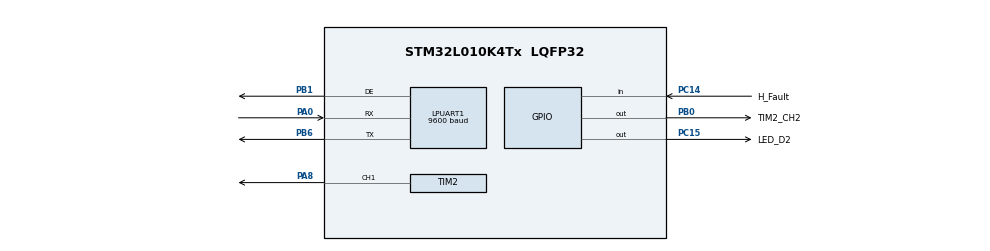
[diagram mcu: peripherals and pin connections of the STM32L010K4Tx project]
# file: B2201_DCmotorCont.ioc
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LPUART1.BaudRate=9600
LPUART1.WordLength=UART_WORDLENGTH_8B
Mcu.Family=STM32L0
Mcu.Name=STM32L010K4Tx
Mcu.Package=LQFP32
PA0-CK_IN.Mode=Asynchronous
PA0-CK_IN.Signal=LPUART1_RX
PA13.Mode=Serial_Wire
PA13.Signal=SYS_SWDIO
PA14.Mode=Serial_Wire
PA14.Signal=SYS_SWCLK
PA8.Signal=S_TIM2_CH1
PB0.GPIO_Label=TIM2_CH2
PB0.Signal=GPIO_Output
PB1.Mode=Hardware Flow Control (RS485)
PB1.Signal=LPUART1_DE
PB6.Mode=Asynchronous
PB6.Signal=LPUART1_TX
PC14-OSC32_IN.GPIO_Label=H_Fault
PC14-OSC32_IN.Signal=GPIO_Input
PC15-OSC32_OUT.GPIO_Label=LED_D2
PC15-OSC32_OUT.Signal=GPIO_Output
ProjectManager.HeapSize=0x200
ProjectManager.StackSize=0x400
ProjectManager.TargetToolchain=STM32CubeIDE
RCC.ADCFreq_Value=16000000
RCC.AHBFreq_Value=24000000
RCC.APB1Freq_Value=24000000
RCC.APB1TimFreq_Value=24000000
RCC.APB2Freq_Value=24000000
RCC.APB2TimFreq_Value=24000000
RCC.HCLKFreq_Value=24000000
RCC.HSE_VALUE=8000000
RCC.HSI16_VALUE=16000000
RCC.HSI_VALUE=16000000
RCC.LSE_VALUE=32768
RCC.MSIClockRange=RCC_MSIRANGE_6
RCC.MSI_VALUE=4194000
RCC.RCC_TIM_PRescaler_Selection=RCC_TIMPRES_DESACTIVATED
RCC.SYSCLKFreq_VALUE=24000000
RCC.SYSCLKSource=RCC_SYSCLKSOURCE_PLLCLK
RCC.VCOOutputFreq_Value=48000000
SH.S_TIM2_CH1.0=TIM2_CH1,PWM Generation1 CH1
TIM2.Channel-PWM\ Generation1\ CH1=TIM_CHANNEL_1
TIM2.Period=1000
TIM2.Prescaler=0
TIM2.Pulse-PWM\ Generation1\ CH1=90
VP_LPTIM1_VS_LPTIM_counterModeInternalClock.Mode=Counts__internal_clock_event_00
VP_TIM21_VS_ClockSourceINT.Mode=Internal
VP_TIM2_VS_ClockSourceINT.Mode=Internal
board=custom

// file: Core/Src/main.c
/* USER CODE BEGIN Header */
/**
  ******************************************************************************
  * @file           : main.c
  * @brief          : Main program body
  ******************************************************************************
  * @attention
  *
  * Copyright (c) 2022 STMicroelectronics.
  * All rights reserved.
  *
  * This software is licensed under terms that can be found in the LICENSE file
  * in the root directory of this software component.
  * If no LICENSE file comes with this software, it is provided AS-IS.
  *
  ******************************************************************************
  */
/* USER CODE END Header */
#include "main.h"

/* USER CODE BEGIN Includes */
#include "stdio.h"

/* USER CODE END Includes */

LPTIM_HandleTypeDef hlptim1;

UART_HandleTypeDef hlpuart1;

TIM_HandleTypeDef htim2;
TIM_HandleTypeDef htim21;

/* USER CODE BEGIN PV */
uint16_t value_adc;
uint16_t counter_global;

/* USER CODE END PV */

void SystemClock_Config(void);
static void MX_GPIO_Init(void);
static void MX_LPUART1_UART_Init(void);
static void MX_TIM2_Init(void);
static void MX_TIM21_Init(void);
static void MX_LPTIM1_Init(void);

/* USER CODE BEGIN 0 */
// connect printf to lpuart1 ** used too much memory so I had to remove it
//int _write(int file, char *ptr, int len)
//{
//	HAL_UART_Transmit(&hlpuart1, (uint8_t*)ptr, len, HAL_MAX_DELAY);
//	return len;
//}

/* USER CODE END 0 */

int main(void)
{

  /* MCU Configuration--------------------------------------------------------*/

  /* Reset of all peripherals, Initializes the Flash interface and the Systick. */
  HAL_Init();

  /* Configure the system clock */
  SystemClock_Config();

  /* Initialize all configured peripherals */
  MX_GPIO_Init();
  MX_LPUART1_UART_Init();
  MX_TIM2_Init();
  MX_TIM21_Init();
  MX_LPTIM1_Init();
  /* USER CODE BEGIN 2 */
//  HAL_ADCEx_Calibration_Start(&hadc, ADC_SINGLE_ENDED);
//  HAL_ADC_Start_DMA(&hadc, (uint32_t*)&value_adc, 1);
  HAL_TIM_PWM_Start(&htim2, TIM_CHANNEL_1);

//  printf("GPIO Init Done /r/n");
  /* USER CODE END 2 */

  /* Infinite loop */
  /* USER CODE BEGIN WHILE */
	int counter =0;

  while (1)
  {

    /* USER CODE END WHILE */

    /* USER CODE BEGIN 3 */

  //-------------------------------------------------
//	  HAL_ADC_Start(&hadc);
//	  printf("current count is: %d\r\n", counter++);
	  counter_global=counter;
	  HAL_Delay(100);
	  HAL_GPIO_WritePin(TIM2_CH2_GPIO_Port, TIM2_CH2_Pin, 1);
      __HAL_TIM_SET_COMPARE(&htim2, TIM_CHANNEL_1,counter); // update pwm compare
      if (counter <1000){
    	  counter++;
      }else counter =0;

/* GPIO Mode simple on off...
     // Forward
	  HAL_GPIO_WritePin(ToshibaIN1_GPIO_Port, ToshibaIN1_Pin, 1);
	  HAL_GPIO_WritePin(ToshibaIN2_GPIO_Port, ToshibaIN2_Pin, 0);
	  HAL_Delay(1000);

	  //coast
	  HAL_GPIO_WritePin(ToshibaIN1_GPIO_Port, ToshibaIN1_Pin, 0);
	  HAL_GPIO_WritePin(ToshibaIN2_GPIO_Port, ToshibaIN2_Pin, 0);
	  HAL_Delay(2000);

	  //reverse
	  HAL_GPIO_WritePin(ToshibaIN1_GPIO_Port, ToshibaIN1_Pin, 0);
	  HAL_GPIO_WritePin(ToshibaIN2_GPIO_Port, ToshibaIN2_Pin, 1);
	  HAL_Delay(1000);

	  //break
	  HAL_GPIO_WritePin(ToshibaIN1_GPIO_Port, ToshibaIN1_Pin, 1);
	  HAL_GPIO_WritePin(ToshibaIN2_GPIO_Port, ToshibaIN2_Pin, 1);
	  HAL_Delay(2000);
*/

	  HAL_GPIO_TogglePin(LED_D2_GPIO_Port, LED_D2_Pin);

  }
  /* USER CODE END 3 */
}

void SystemClock_Config(void)
{
  LL_FLASH_SetLatency(LL_FLASH_LATENCY_1);
  while(LL_FLASH_GetLatency()!= LL_FLASH_LATENCY_1)
  {
  }
  LL_PWR_SetRegulVoltageScaling(LL_PWR_REGU_VOLTAGE_SCALE1);
  LL_RCC_HSI_Enable();

   /* Wait till HSI is ready */
  while(LL_RCC_HSI_IsReady() != 1)
  {

  }
  LL_RCC_HSI_SetCalibTrimming(16);
  LL_RCC_PLL_ConfigDomain_SYS(LL_RCC_PLLSOURCE_HSI, LL_RCC_PLL_MUL_3, LL_RCC_PLL_DIV_2);
  LL_RCC_PLL_Enable();

   /* Wait till PLL is ready */
  while(LL_RCC_PLL_IsReady() != 1)
  {

  }
  LL_RCC_SetAHBPrescaler(LL_RCC_SYSCLK_DIV_1);
  LL_RCC_SetAPB1Prescaler(LL_RCC_APB1_DIV_1);
  LL_RCC_SetAPB2Prescaler(LL_RCC_APB2_DIV_1);
  LL_RCC_SetSysClkSource(LL_RCC_SYS_CLKSOURCE_PLL);

   /* Wait till System clock is ready */
  while(LL_RCC_GetSysClkSource() != LL_RCC_SYS_CLKSOURCE_STATUS_PLL)
  {

  }
  LL_SetSystemCoreClock(24000000);

   /* Update the time base */
  if (HAL_InitTick (TICK_INT_PRIORITY) != HAL_OK)
  {
    Error_Handler();
  }
  LL_RCC_SetLPUARTClockSource(LL_RCC_LPUART1_CLKSOURCE_PCLK1);
  LL_RCC_SetLPTIMClockSource(LL_RCC_LPTIM1_CLKSOURCE_PCLK1);
}

static void MX_LPTIM1_Init(void)
{

  hlptim1.Instance = LPTIM1;
  hlptim1.Init.Clock.Source = LPTIM_CLOCKSOURCE_APBCLOCK_LPOSC;
  hlptim1.Init.Clock.Prescaler = LPTIM_PRESCALER_DIV1;
  hlptim1.Init.Trigger.Source = LPTIM_TRIGSOURCE_SOFTWARE;
  hlptim1.Init.OutputPolarity = LPTIM_OUTPUTPOLARITY_HIGH;
  hlptim1.Init.UpdateMode = LPTIM_UPDATE_IMMEDIATE;
  hlptim1.Init.CounterSource = LPTIM_COUNTERSOURCE_INTERNAL;
  if (HAL_LPTIM_Init(&hlptim1) != HAL_OK)
  {
    Error_Handler();
  }

}

static void MX_LPUART1_UART_Init(void)
{

  hlpuart1.Instance = LPUART1;
  hlpuart1.Init.BaudRate = 9600;
  hlpuart1.Init.WordLength = UART_WORDLENGTH_8B;
  hlpuart1.Init.StopBits = UART_STOPBITS_1;
  hlpuart1.Init.Parity = UART_PARITY_NONE;
  hlpuart1.Init.Mode = UART_MODE_TX_RX;
  hlpuart1.Init.HwFlowCtl = UART_HWCONTROL_NONE;
  hlpuart1.Init.OneBitSampling = UART_ONE_BIT_SAMPLE_DISABLE;
  hlpuart1.AdvancedInit.AdvFeatureInit = UART_ADVFEATURE_NO_INIT;
  if (HAL_RS485Ex_Init(&hlpuart1, UART_DE_POLARITY_HIGH, 0, 0) != HAL_OK)
  {
    Error_Handler();
  }

}

static void MX_TIM2_Init(void)
{

  TIM_ClockConfigTypeDef sClockSourceConfig = {0};
  TIM_MasterConfigTypeDef sMasterConfig = {0};
  TIM_OC_InitTypeDef sConfigOC = {0};

  htim2.Instance = TIM2;
  htim2.Init.Prescaler = 0;
  htim2.Init.CounterMode = TIM_COUNTERMODE_UP;
  htim2.Init.Period = 1000;
  htim2.Init.ClockDivision = TIM_CLOCKDIVISION_DIV1;
  htim2.Init.AutoReloadPreload = TIM_AUTORELOAD_PRELOAD_DISABLE;
  if (HAL_TIM_Base_Init(&htim2) != HAL_OK)
  {
    Error_Handler();
  }
  sClockSourceConfig.ClockSource = TIM_CLOCKSOURCE_INTERNAL;
  if (HAL_TIM_ConfigClockSource(&htim2, &sClockSourceConfig) != HAL_OK)
  {
    Error_Handler();
  }
  if (HAL_TIM_PWM_Init(&htim2) != HAL_OK)
  {
    Error_Handler();
  }
  sMasterConfig.MasterOutputTrigger = TIM_TRGO_RESET;
  sMasterConfig.MasterSlaveMode = TIM_MASTERSLAVEMODE_DISABLE;
  if (HAL_TIMEx_MasterConfigSynchronization(&htim2, &sMasterConfig) != HAL_OK)
  {
    Error_Handler();
  }
  sConfigOC.OCMode = TIM_OCMODE_PWM1;
  sConfigOC.Pulse = 90;
  sConfigOC.OCPolarity = TIM_OCPOLARITY_HIGH;
  sConfigOC.OCFastMode = TIM_OCFAST_DISABLE;
  if (HAL_TIM_PWM_ConfigChannel(&htim2, &sConfigOC, TIM_CHANNEL_1) != HAL_OK)
  {
    Error_Handler();
  }
  HAL_TIM_MspPostInit(&htim2);

}

static void MX_TIM21_Init(void)
{

  TIM_ClockConfigTypeDef sClockSourceConfig = {0};
  TIM_MasterConfigTypeDef sMasterConfig = {0};

  htim21.Instance = TIM21;
  htim21.Init.Prescaler = 0;
  htim21.Init.CounterMode = TIM_COUNTERMODE_UP;
  htim21.Init.Period = 65535;
  htim21.Init.ClockDivision = TIM_CLOCKDIVISION_DIV1;
  htim21.Init.AutoReloadPreload = TIM_AUTORELOAD_PRELOAD_DISABLE;
  if (HAL_TIM_Base_Init(&htim21) != HAL_OK)
  {
    Error_Handler();
  }
  sClockSourceConfig.ClockSource = TIM_CLOCKSOURCE_INTERNAL;
  if (HAL_TIM_ConfigClockSource(&htim21, &sClockSourceConfig) != HAL_OK)
  {
    Error_Handler();
  }
  sMasterConfig.MasterOutputTrigger = TIM_TRGO_RESET;
  sMasterConfig.MasterSlaveMode = TIM_MASTERSLAVEMODE_DISABLE;
  if (HAL_TIMEx_MasterConfigSynchronization(&htim21, &sMasterConfig) != HAL_OK)
  {
    Error_Handler();
  }

}

static void MX_GPIO_Init(void)
{
  GPIO_InitTypeDef GPIO_InitStruct = {0};

  /* GPIO Ports Clock Enable */
  __HAL_RCC_GPIOC_CLK_ENABLE();
  __HAL_RCC_GPIOA_CLK_ENABLE();
  __HAL_RCC_GPIOB_CLK_ENABLE();

  /*Configure GPIO pin Output Level */
  HAL_GPIO_WritePin(LED_D2_GPIO_Port, LED_D2_Pin, GPIO_PIN_RESET);

  /*Configure GPIO pin Output Level */
  HAL_GPIO_WritePin(TIM2_CH2_GPIO_Port, TIM2_CH2_Pin, GPIO_PIN_RESET);

  /*Configure GPIO pin : H_Fault_Pin */
  GPIO_InitStruct.Pin = H_Fault_Pin;
  GPIO_InitStruct.Mode = GPIO_MODE_INPUT;
  GPIO_InitStruct.Pull = GPIO_NOPULL;
  HAL_GPIO_Init(H_Fault_GPIO_Port, &GPIO_InitStruct);

  /*Configure GPIO pin : LED_D2_Pin */
  GPIO_InitStruct.Pin = LED_D2_Pin;
  GPIO_InitStruct.Mode = GPIO_MODE_OUTPUT_PP;
  GPIO_InitStruct.Pull = GPIO_NOPULL;
  GPIO_InitStruct.Speed = GPIO_SPEED_FREQ_LOW;
  HAL_GPIO_Init(LED_D2_GPIO_Port, &GPIO_InitStruct);

  /*Configure GPIO pin : TIM2_CH2_Pin */
  GPIO_InitStruct.Pin = TIM2_CH2_Pin;
  GPIO_InitStruct.Mode = GPIO_MODE_OUTPUT_PP;
  GPIO_InitStruct.Pull = GPIO_NOPULL;
  GPIO_InitStruct.Speed = GPIO_SPEED_FREQ_LOW;
  HAL_GPIO_Init(TIM2_CH2_GPIO_Port, &GPIO_InitStruct);

}

void Error_Handler(void)
{
  __disable_irq();
  while (1)
  {
  }
}
